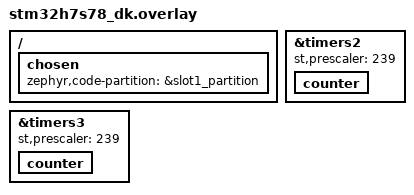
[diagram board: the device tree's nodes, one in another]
/* build with --sysbuild to execute in external NOR */
/ {
	chosen {
		zephyr,code-partition = &slot1_partition;
	};
};

&timers2 {
	st,prescaler = <239>;
	counter {
		status = "okay";
	};
};

&timers3 {
	st,prescaler = <239>;
	counter {
		status = "okay";
	};
};
/*
&timers4 {
	st,prescaler = <239>;
	counter {
		status = "okay";
	};
};

&timers5 {
	st,prescaler = <239>;
	counter {
		status = "okay";
	};
};

&timers6 {
	st,prescaler = <239>;
	counter {
		status = "okay";
	};
};

&timers7 {
	st,prescaler = <239>;
	counter {
		status = "okay";
	};
};

&timers12 {
	st,prescaler = <239>;
	counter {
		status = "okay";
	};
};

&timers13 {
	st,prescaler = <239>;
	counter {
		status = "okay";
	};
};

&timers14 {
	st,prescaler = <239>;
	counter {
		status = "okay";
	};
};
*/
